VERSION ""

NS_ :

BS_:

BU_: XXX DSU HCU EPS IPAS

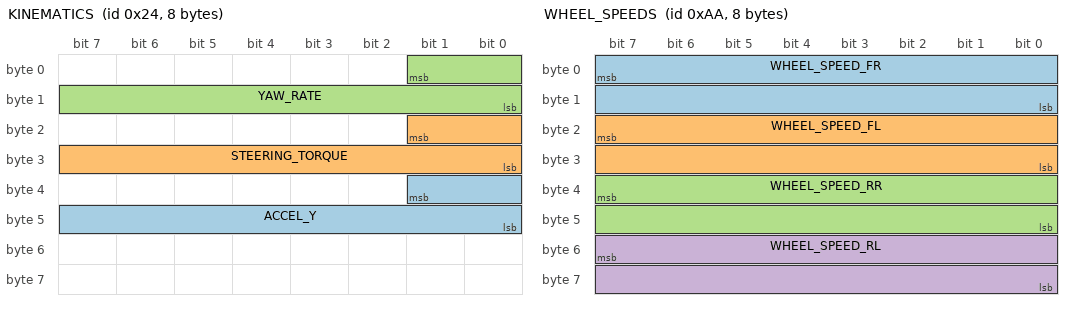
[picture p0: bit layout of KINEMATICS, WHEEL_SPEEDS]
BO_ 36 KINEMATICS: 8 XXX
 SG_ ACCEL_Y : 33|10@0+ (1,-512) [0|65535] "" XXX
 SG_ STEERING_TORQUE : 17|10@0+ (1,-512) [0|65535] "" XXX
 SG_ YAW_RATE : 1|10@0+ (1,-512) [0|65535] "" XXX

BO_ 166 BRAKE: 8 XXX
 SG_ BRAKE_AMOUNT : 7|8@0+ (1,0) [0|255] "" XXX
 SG_ BRAKE_PEDAL : 23|8@0+ (1,0) [0|255] "" XXX

BO_ 170 WHEEL_SPEEDS: 8 XXX
 SG_ WHEEL_SPEED_FR : 7|16@0+ (0.0062,-67.67) [0|250] "mph" XXX
 SG_ WHEEL_SPEED_FL : 23|16@0+ (0.0062,-67.67) [0|250] "mph" XXX
 SG_ WHEEL_SPEED_RR : 39|16@0+ (0.0062,-67.67) [0|250] "mph" XXX
 SG_ WHEEL_SPEED_RL : 55|16@0+ (0.0062,-67.67) [0|250] "mph" XXX
